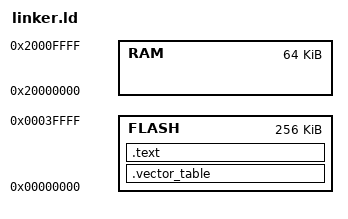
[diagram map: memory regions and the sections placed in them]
/* Layout of stm
MEMORY
{
  FLASH (rx)  : ORIGIN = 0x08000000, LENGTH = 32K
  RAM   (rwx) : ORIGIN = 0x20000000, LENGTH = 10K
}
*/

/* Memory layout of the LM3S6965 microcontroller */
MEMORY
{
  FLASH : ORIGIN = 0x00000000, LENGTH = 256K
  RAM   : ORIGIN = 0x20000000, LENGTH = 64K
}

/* The entry point is the reset handler */
ENTRY(reset_handler);

EXTERN(RESET_VECTOR);

SECTIONS
{
  .vector_table ORIGIN(FLASH) :
  {
    /* First entry: initial Stack Pointer value */
    LONG(ORIGIN(RAM) + LENGTH(RAM));

    /* Second entry: reset vector */
    KEEP(*(.vector_table.reset_vector));
  } > FLASH

  .text :
  {
    *(.text .text.*);
  } > FLASH

  /DISCARD/ :
  {
    *(.ARM.exidx .ARM.exidx.*);
  }
}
